AUTOSAR XML (schema 4-0-3)
package /ComponentTypes
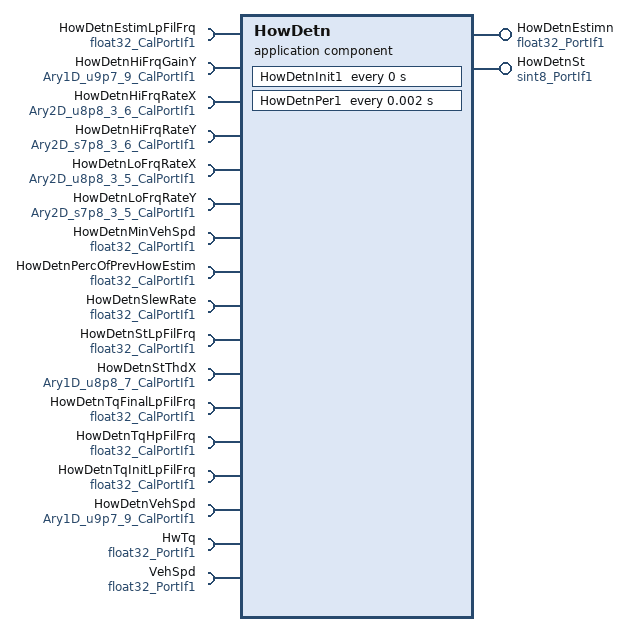
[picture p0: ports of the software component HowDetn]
  application sw component type HowDetn
    provide port HowDetnEstimn: nonqueued-sender-com-spec{data-element=Val, init-value=0.5}, provided-interface=float32_PortIf1
    provide port HowDetnSt: nonqueued-sender-com-spec{data-element=Val, init-value=0}, provided-interface=sint8_PortIf1
    17 x require port:
      HowDetnEstimLpFilFrq: parameter-require-com-spec{init-value=0.5, parameter=Val}, required-interface=float32_CalPortIf1
      HowDetnHiFrqGainY: parameter-require-com-spec{init-value=9 x 2227, parameter=Ary1D}, required-interface=Ary1D_u9p7_9_CalPortIf1
      HowDetnHiFrqRateX: parameter-require-com-spec{init-value=[[0, 26, 64, 77, 128, 256], [0, 26, 64, 77, 128, 256], [0, 26, 64, 77, 128, 256]], parameter=Ary2D}, required-interface=Ary2D_u8p8_3_6_CalPortIf1
      HowDetnHiFrqRateY: parameter-require-com-spec{init-value=[[-1280, -256, 0, 0, 5120, 5120], [-1280, -256, 0, 0, 5120, 5120], [-1280, -256, 0, 0, 5120, 5120]], parameter=Ary2D}, required-interface=Ary2D_s7p8_3_6_CalPortIf1
      HowDetnLoFrqRateX: parameter-require-com-spec{init-value=[[0, 19, 51, 64, 256], [0, 19, 51, 64, 256], [0, 19, 51, 64, 256]], parameter=Ary2D}, required-interface=Ary2D_u8p8_3_5_CalPortIf1
      HowDetnLoFrqRateY: parameter-require-com-spec{init-value=[[-512, -128, 0, 0, 23040], [-512, -128, 0, 0, 23040], [-512, -128, 0, 0, 23040]], parameter=Ary2D}, required-interface=Ary2D_s7p8_3_5_CalPortIf1
      HowDetnMinVehSpd: parameter-require-com-spec{init-value=10, parameter=Val}, required-interface=float32_CalPortIf1
      HowDetnPercOfPrevHowEstim: parameter-require-com-spec{init-value=0.99, parameter=Val}, required-interface=float32_CalPortIf1
      HowDetnSlewRate: parameter-require-com-spec{init-value=2, parameter=Val}, required-interface=float32_CalPortIf1
      HowDetnStLpFilFrq: parameter-require-com-spec{init-value=2, parameter=Val}, required-interface=float32_CalPortIf1
      HowDetnStThdX: parameter-require-com-spec{init-value=[0, 15, 64, 90, 166, 192, 241], parameter=Ary1D}, required-interface=Ary1D_u8p8_7_CalPortIf1
      HowDetnTqFinalLpFilFrq: parameter-require-com-spec{init-value=1, parameter=Val}, required-interface=float32_CalPortIf1
      HowDetnTqHpFilFrq: parameter-require-com-spec{init-value=7, parameter=Val}, required-interface=float32_CalPortIf1
      HowDetnTqInitLpFilFrq: parameter-require-com-spec{init-value=7, parameter=Val}, required-interface=float32_CalPortIf1
      HowDetnVehSpd: parameter-require-com-spec{init-value=[1280, 2560, 3840, 5120, 6400, 7680, 8960, 10240, 12800], parameter=Ary1D}, required-interface=Ary1D_u9p7_9_CalPortIf1
      HwTq: nonqueued-receiver-com-spec{data-element=Val, filter=data-filter-type=ALWAYS, init-value=0}, required-interface=float32_PortIf1
      VehSpd: nonqueued-receiver-com-spec{data-element=Val, filter=data-filter-type=ALWAYS, init-value=0}, required-interface=float32_PortIf1
    behavior HowDetn_InternalBehavior
      ar-typed-per-instance-memorys:
        11 x data, all with sw-calibration-access=READ-ONLY:
          dHowDetnAbsHiFrqTq: type=float32
          dHowDetnAbsLoFrqTq: type=float32
          EstimLpFil: type=FilLpRec1
          FinalLpFil: type=FilLpRec1
          IniLpFil{1..3}: type=FilLpRec1
          PrevCalcdHowEstim: type=float32
          PrevHowEstim: type=float32
          StLpFil: type=FilLpRec1
          TqHpFil: type=FilHpRec1
      timing event HowDetn_InitEvent: start-on-event=HowDetnInit1, period=0
      timing event TMT_HowDetnPer1: start-on-event=HowDetnPer1, period=0.002
      runnable HowDetnInit1
      runnable HowDetnPer1
        data-receive-point-by-arguments:
          access REC_HwTq_Val: accessed-variable=HwTq.Val
          access REC_VehSpd_Val: accessed-variable=VehSpd.Val
        data-send-points:
          access SEND_HowDetnEstimn_Val: accessed-variable=HowDetnEstimn.Val
          access SEND_HowDetnSt_Val: accessed-variable=HowDetnSt.Val
  swc implementation HowDetn_Implementation: behavior=HowDetn_InternalBehavior
    code-descriptors:
      code Default: artifact-descriptors=autosar-engineering-object={short-label=Default, category=SWSRC}
